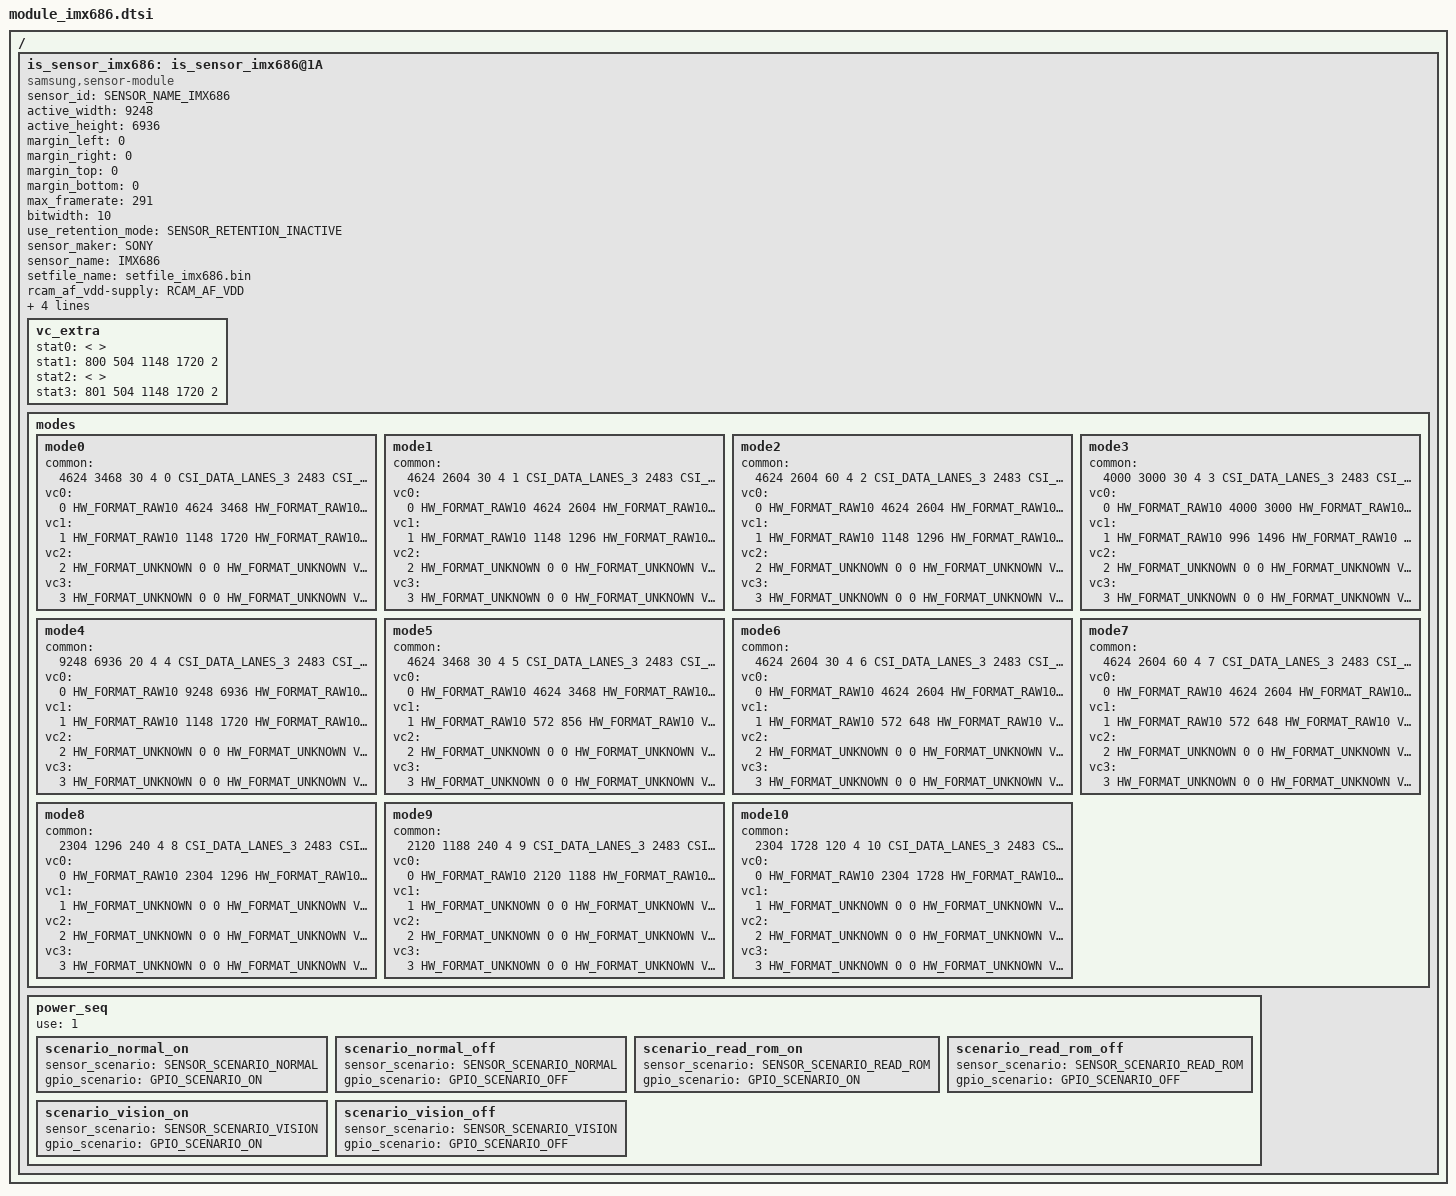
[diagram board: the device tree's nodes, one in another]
/*
 * SAMSUNG EXYNOSxxxx board camera device tree source
 *
 * Copyright (c) 2019 Samsung Electronics Co., Ltd.
 *		http://www.samsung.com
 *
 * This program is free software; you can redistribute it and/or modify
 * it under the terms of the GNU General Public License version 2 as
 * published by the Free Software Foundation.
 */

#include <dt-bindings/camera/exynos_is_dt.h>

#ifndef USE_VENDOR_PWR_PIN_NAME
#define RCAM_AF_VDD	<>
#define IMX686_AVDD1	<>
#define IMX686_AVDD2	<>
#define IMX686_DVDD	<>
#define IMX686_IOVDD	<>
#endif

/ {
	fragment@camera {
		target-path = "/";
		__overlay__ {
			is_sensor_imx686: is_sensor_imx686@1A {
				compatible = "samsung,sensor-module";

				/* common */
				sensor_id = <SENSOR_NAME_IMX686>;
				active_width = <9248>;
				active_height = <6936>;
				margin_left = <0>;
				margin_right = <0>;
				margin_top = <0>;
				margin_bottom = <0>;
				max_framerate = <291>;
				bitwidth = <10>;
				use_retention_mode = <SENSOR_RETENTION_INACTIVE>;
				sensor_maker = "SONY";
				sensor_name = "IMX686";
				setfile_name = "setfile_imx686.bin";

				rcam_af_vdd-supply = RCAM_AF_VDD;
				imx686_avdd1-supply = IMX686_AVDD1;
				imx686_avdd2-supply = IMX686_AVDD2;
				imx686_dvdd-supply = IMX686_DVDD;
				imx686_iovdd-supply = IMX686_IOVDD;

				status = "okay";

				vc_extra {
					/* ex) statX = <stat_type, sensor_mode, max_width, max_height, max_element> */
					/* VC_BUF_DATA_TYPE_SENSOR_STAT1 */
					stat0 = </* not avaliable */>;
					/* VC_BUF_DATA_TYPE_GENERAL_STAT1 */
					stat1 = </*VC_STAT_TYPE_PDP_1_1_PDAF_STAT0*/ 800    /*VC_SENSOR_MODE_IMX_2X1OCL_2_TAIL*/ 504 1148 1720 2>;
					/* VC_BUF_DATA_TYPE_SENSOR_STAT2 */
					stat2 = </* not avaliable */>;
					/* VC_BUF_DATA_TYPE_GENERAL_STAT2 */
					stat3 = </*VC_STAT_TYPE_PDP_1_1_PDAF_STAT1*/ 801    /*VC_SENSOR_MODE_IMX_2X1OCL_2_TAIL*/ 504 1148 1720 2>;
				};

/*
 * [Mode Information]
 *
 * Reference File :
 * MP version : IMX686-FAKH5-SEC-CPHY-26M_RegisterSetting_ver6.00-8.00_b8_MP_Exy_200218.xlsx
 * ES version : IMX686-FAKH5-SEC-CPHY-26M_RegisterSetting_ver6.00-7.00_b8_ES_Exy_200218.xlsx
 * Update Data    : 2020-02-20
 * Author         : takkyoum.kim
 *
 * - Global Setting with ImageQuality setting -
 *
 * - 2x2 BIN For Still Preview / Capture / Recording -
 *    [  0 ] 2Bin_A2   : 2x2 Binning 4624X3468 30fps      : Single Still Preview/Capture (4:3)   ,  MIPI lane: 3, MIPI data rate(Mbps/lane): 2483
 *    [  1 ] 2Bin_B     : 2x2 Binning 4624X2604 30fps      : Single Still Preview/Capture (16:9)  ,  MIPI lane: 3, MIPI data rate(Mbps/lane): 2483
 *    [  2 ] 2Bin_C     : 2x2 Binning 4624X2604 60fps      : Single Still Preview/Capture (16:9)  ,  MIPI lane: 3, MIPI data rate(Mbps/lane): 2483
 *    [  3 ] 2Bin_D     : 2x2 Binning 4000X3000 30fps      : Single Still Preview/Capture (4:3)   ,  MIPI lane: 3, MIPI data rate(Mbps/lane): 2483
 *
 * - Remosaic Full For Still Remosaic Capture -
 *    [  4 ] Full          : Remosaic Full 9248x6936 20fps   : Single Still Remosaic Capture (4:3)  ,  MIPI lane: 3, MIPI data rate(Mbps/lane): 2483
 *
 * - Remosaic Crop For RemosaicCropZoom Mode -
 *    [  5 ] Full_CropA2 : Remosaic Crop 4624x3468 30fps : Single Still Remosaic Preview (4:3)   ,  MIPI lane: 3, MIPI data rate(Mbps/lane): 2483
 *    [  6 ] Full_CropB  : Remosaic Crop 4624x2604 30fps : Single Still Remosaic Preview (16:9)  ,  MIPI lane: 3, MIPI data rate(Mbps/lane): 2483
 *    [  7 ] Full_CropC  : Remosaic Crop 4624x2604 60fps : Single Still Remosaic Preview (16:9)  ,  MIPI lane: 3, MIPI data rate(Mbps/lane): 2483
 *
 * - V2H2 For HighSpeed Recording/FastAE -
 *    [  8 ] V2H2_SSL    : V2H2 SlowMotion 2304x1296 240fps : Slow Motion Preview        (16:9)   ,  MIPI lane: 3, MIPI data rate(Mbps/lane): 2483
 *    [  9 ] V2H2_SSL_B : V2H2 SlowMotion 2120x1188 240fps : Slow Motion Crop Preview (16:9)   ,  MIPI lane: 3, MIPI data rate(Mbps/lane): 2483
 *    [ 10 ] V2H2_FAE    : V2H2 FastAE      2304x1728 120fps : Fast AE                          (4:3)    ,  MIPI lane: 3, MIPI data rate(Mbps/lane): 2483
 *
 * - SuperNightMode (none USED) -
 *    [ 11 ] SNM         : SuperNightMode  4624x3468 24fps   : Dual Still Preview/Capture (4:3)  ,  MIPI lane: 3, MIPI data rate(Mbps/lane): 2483
 *
 */

				/* sensor modes */
				modes {
						/* common = <width, height, fps, settle, mode, lane, speed, interleave, lrte, pd_mode> */
						/* vcX = <map, hwformat, width, height, hwformat, type, width, height> */

					/* 2x2 BIN For Single Still Preview & Capture */
					mode0 {
						common = <4624 3468 30 4 0 CSI_DATA_LANES_3 2483 CSI_MODE_VC_DT LRTE_DISABLE PD_MSPD_TAIL EX_NONE>;
						vc0 = </* in */ 0 HW_FORMAT_RAW10 4624 3468		/* out */ HW_FORMAT_RAW10 VC_NOTHING 0 0>;
						vc1 = </* in */ 1 HW_FORMAT_RAW10 1148 1720		/* out */ HW_FORMAT_RAW10 VC_NOTHING 0 0>;
						vc2 = </* in */ 2 HW_FORMAT_UNKNOWN 0 0			/* out */ HW_FORMAT_UNKNOWN VC_NOTHING 0 0>;
						vc3 = </* in */ 3 HW_FORMAT_UNKNOWN 0 0			/* out */ HW_FORMAT_UNKNOWN VC_NOTHING 0 0>;
					};
					mode1 {
						common = <4624 2604 30 4 1 CSI_DATA_LANES_3 2483 CSI_MODE_VC_DT LRTE_DISABLE PD_MSPD_TAIL EX_NONE>;
						vc0 = </* in */ 0 HW_FORMAT_RAW10 4624 2604		/* out */ HW_FORMAT_RAW10 VC_NOTHING 0 0>;
						vc1 = </* in */ 1 HW_FORMAT_RAW10 1148 1296		/* out */ HW_FORMAT_RAW10 VC_NOTHING 0 0>;
						vc2 = </* in */ 2 HW_FORMAT_UNKNOWN 0 0			/* out */ HW_FORMAT_UNKNOWN VC_NOTHING 0 0>;
						vc3 = </* in */ 3 HW_FORMAT_UNKNOWN 0 0			/* out */ HW_FORMAT_UNKNOWN VC_NOTHING 0 0>;
					};
					mode2 {
						common = <4624 2604 60 4 2 CSI_DATA_LANES_3 2483 CSI_MODE_VC_DT LRTE_DISABLE PD_MSPD_TAIL EX_NONE>;
						vc0 = </* in */ 0 HW_FORMAT_RAW10 4624 2604		/* out */ HW_FORMAT_RAW10 VC_NOTHING 0 0>;
						vc1 = </* in */ 1 HW_FORMAT_RAW10 1148 1296		/* out */ HW_FORMAT_RAW10 VC_NOTHING 0 0>;
						vc2 = </* in */ 2 HW_FORMAT_UNKNOWN 0 0			/* out */ HW_FORMAT_UNKNOWN VC_NOTHING 0 0>;
						vc3 = </* in */ 3 HW_FORMAT_UNKNOWN 0 0			/* out */ HW_FORMAT_UNKNOWN VC_NOTHING 0 0>;
					};
					mode3 {
						common = <4000 3000 30 4 3 CSI_DATA_LANES_3 2483 CSI_MODE_VC_DT LRTE_DISABLE PD_MSPD_TAIL EX_NONE>;
						vc0 = </* in */ 0 HW_FORMAT_RAW10 4000 3000		/* out */ HW_FORMAT_RAW10 VC_NOTHING 0 0>;
						vc1 = </* in */ 1 HW_FORMAT_RAW10 996 1496		/* out */ HW_FORMAT_RAW10 VC_NOTHING 0 0>;
						vc2 = </* in */ 2 HW_FORMAT_UNKNOWN 0 0			/* out */ HW_FORMAT_UNKNOWN VC_NOTHING 0 0>;
						vc3 = </* in */ 3 HW_FORMAT_UNKNOWN 0 0			/* out */ HW_FORMAT_UNKNOWN VC_NOTHING 0 0>;
					};

					/* REMOSAIC For Single Still Preview & Capture */
					mode4 {
						common = <9248 6936 20 4 4 CSI_DATA_LANES_3 2483 CSI_MODE_VC_DT LRTE_DISABLE PD_MSPD_TAIL EX_NONE>;
						vc0 = </* in */ 0 HW_FORMAT_RAW10 9248 6936		/* out */ HW_FORMAT_RAW10 VC_NOTHING 0 0>;
						vc1 = </* in */ 1 HW_FORMAT_RAW10 1148 1720		/* out */ HW_FORMAT_RAW10 VC_NOTHING 0 0>;
						vc2 = </* in */ 2 HW_FORMAT_UNKNOWN 0 0			/* out */ HW_FORMAT_UNKNOWN VC_NOTHING 0 0>;
						vc3 = </* in */ 3 HW_FORMAT_UNKNOWN 0 0			/* out */ HW_FORMAT_UNKNOWN VC_NOTHING 0 0>;
					};

					/* REMOSAIC CROP For RemosaicCropZoom Mode */
					mode5 {
						common = <4624 3468 30 4 5 CSI_DATA_LANES_3 2483 CSI_MODE_VC_DT LRTE_DISABLE PD_MSPD_TAIL EX_LOW_RES_TETRA>;
						vc0 = </* in */ 0 HW_FORMAT_RAW10 4624 3468		/* out */ HW_FORMAT_RAW10 VC_NOTHING 0 0>;
						vc1 = </* in */ 1 HW_FORMAT_RAW10 572 856		/* out */ HW_FORMAT_RAW10 VC_NOTHING 0 0>;
						vc2 = </* in */ 2 HW_FORMAT_UNKNOWN 0 0			/* out */ HW_FORMAT_UNKNOWN VC_NOTHING 0 0>;
						vc3 = </* in */ 3 HW_FORMAT_UNKNOWN 0 0			/* out */ HW_FORMAT_UNKNOWN VC_NOTHING 0 0>;
					};
					mode6 {
						common = <4624 2604 30 4 6 CSI_DATA_LANES_3 2483 CSI_MODE_VC_DT LRTE_DISABLE PD_MSPD_TAIL EX_LOW_RES_TETRA>;
						vc0 = </* in */ 0 HW_FORMAT_RAW10 4624 2604		/* out */ HW_FORMAT_RAW10 VC_NOTHING 0 0>;
						vc1 = </* in */ 1 HW_FORMAT_RAW10 572 648		/* out */ HW_FORMAT_RAW10 VC_NOTHING 0 0>;
						vc2 = </* in */ 2 HW_FORMAT_UNKNOWN 0 0			/* out */ HW_FORMAT_UNKNOWN VC_NOTHING 0 0>;
						vc3 = </* in */ 3 HW_FORMAT_UNKNOWN 0 0			/* out */ HW_FORMAT_UNKNOWN VC_NOTHING 0 0>;
					};
					mode7 {
						common = <4624 2604 60 4 7 CSI_DATA_LANES_3 2483 CSI_MODE_VC_DT LRTE_DISABLE PD_MSPD_TAIL EX_LOW_RES_TETRA>;
						vc0 = </* in */ 0 HW_FORMAT_RAW10 4624 2604		/* out */ HW_FORMAT_RAW10 VC_NOTHING 0 0>;
						vc1 = </* in */ 1 HW_FORMAT_RAW10 572 648		/* out */ HW_FORMAT_RAW10 VC_NOTHING 0 0>;
						vc2 = </* in */ 2 HW_FORMAT_UNKNOWN 0 0			/* out */ HW_FORMAT_UNKNOWN VC_NOTHING 0 0>;
						vc3 = </* in */ 3 HW_FORMAT_UNKNOWN 0 0			/* out */ HW_FORMAT_UNKNOWN VC_NOTHING 0 0>;
					};

					/* V2H2 For HighSpeed Recording & FastAE */
					mode8{
						common = <2304 1296 240 4 8 CSI_DATA_LANES_3 2483 CSI_MODE_VC_DT LRTE_DISABLE PD_NONE EX_NONE>;
						vc0 = </* in */ 0 HW_FORMAT_RAW10 2304 1296		/* out */ HW_FORMAT_RAW10 VC_NOTHING 0 0>;
						vc1 = </* in */ 1 HW_FORMAT_UNKNOWN 0 0			/* out */ HW_FORMAT_UNKNOWN VC_NOTHING 0 0>;
						vc2 = </* in */ 2 HW_FORMAT_UNKNOWN 0 0			/* out */ HW_FORMAT_UNKNOWN VC_NOTHING 0 0>;
						vc3 = </* in */ 3 HW_FORMAT_UNKNOWN 0 0			/* out */ HW_FORMAT_UNKNOWN VC_NOTHING 0 0>;
					};
					mode9{
						common = <2120 1188 240 4 9 CSI_DATA_LANES_3 2483 CSI_MODE_VC_DT LRTE_DISABLE PD_NONE EX_NONE>;
						vc0 = </* in */ 0 HW_FORMAT_RAW10 2120 1188		/* out */ HW_FORMAT_RAW10 VC_NOTHING 0 0>;
						vc1 = </* in */ 1 HW_FORMAT_UNKNOWN 0 0			/* out */ HW_FORMAT_UNKNOWN VC_NOTHING 0 0>;
						vc2 = </* in */ 2 HW_FORMAT_UNKNOWN 0 0			/* out */ HW_FORMAT_UNKNOWN VC_NOTHING 0 0>;
						vc3 = </* in */ 3 HW_FORMAT_UNKNOWN 0 0			/* out */ HW_FORMAT_UNKNOWN VC_NOTHING 0 0>;
					};
					mode10{
						common = <2304 1728 120 4 10 CSI_DATA_LANES_3 2483 CSI_MODE_VC_DT LRTE_DISABLE PD_NONE EX_NONE>;
						vc0 = </* in */ 0 HW_FORMAT_RAW10 2304 1728		/* out */ HW_FORMAT_RAW10 VC_NOTHING 0 0>;
						vc1 = </* in */ 1 HW_FORMAT_UNKNOWN 0 0			/* out */ HW_FORMAT_UNKNOWN VC_NOTHING 0 0>;
						vc2 = </* in */ 2 HW_FORMAT_UNKNOWN 0 0			/* out */ HW_FORMAT_UNKNOWN VC_NOTHING 0 0>;
						vc3 = </* in */ 3 HW_FORMAT_UNKNOWN 0 0			/* out */ HW_FORMAT_UNKNOWN VC_NOTHING 0 0>;
					};
#if 0
					/* SuperNightMode (none USED) */
					mode11{
						common = <4624 3468 24 4 11 CSI_DATA_LANES_3 2483 CSI_MODE_VC_DT LRTE_DISABLE PD_MSPD_TAIL EX_NONE>;
						vc0 = </* in */ 0 HW_FORMAT_RAW10 4624 3468		/* out */ HW_FORMAT_RAW10 VC_NOTHING 0 0>;
						vc1 = </* in */ 1 HW_FORMAT_RAW10 1148 1720		/* out */ HW_FORMAT_RAW10 VC_NOTHING 0 0>;
						vc2 = </* in */ 2 HW_FORMAT_UNKNOWN 0 0			/* out */ HW_FORMAT_UNKNOWN VC_NOTHING 0 0>;
						vc3 = </* in */ 3 HW_FORMAT_UNKNOWN 0 0			/* out */ HW_FORMAT_UNKNOWN VC_NOTHING 0 0>;
					};
#endif
				};

				power_seq {
					use = <1>;
					scenario_normal_on {
						sensor_scenario = <SENSOR_SCENARIO_NORMAL>;
						gpio_scenario = <GPIO_SCENARIO_ON>;

						/* A start node number should be over the 10 for reserved number 0~9. */
						/* pname = "name"; 		pin = <act value dealy voltage>;	gpio = <gpx# # 0x1>; */
					};

					scenario_normal_off {
						sensor_scenario = <SENSOR_SCENARIO_NORMAL>;
						gpio_scenario = <GPIO_SCENARIO_OFF>;

						/* A start node number should be over the 10 for reserved number 0~9. */
						/* pname = "name"; 		pin = <act value dealy voltage>;	gpio = <gpx# # 0x1>; */
					};

					scenario_read_rom_on {
						sensor_scenario = <SENSOR_SCENARIO_READ_ROM>;
						gpio_scenario = <GPIO_SCENARIO_ON>;

						/* A start node number should be over the 10 for reserved number 0~9. */
						/* pname = "name";		pin = <act value dealy voltage>;	gpio = <gpx# # 0x1>; */
					};

					scenario_read_rom_off {
						sensor_scenario = <SENSOR_SCENARIO_READ_ROM>;
						gpio_scenario = <GPIO_SCENARIO_OFF>;

						/* A start node number should be over the 10 for reserved number 0~9. */
						/* pname = "name"; 		pin = <act value dealy voltage>; 	gpio = <gpx# # 0x1>; */
					};

					scenario_vision_on {
						sensor_scenario = <SENSOR_SCENARIO_VISION>;
						gpio_scenario = <GPIO_SCENARIO_ON>;

						/* A start node number should be over the 10 for reserved number 0~9. */
						/* pname = "name"; 		pin = <act value dealy voltage>;	gpio = <gpx# # 0x1>; */
					};

					scenario_vision_off {
						sensor_scenario = <SENSOR_SCENARIO_VISION>;
						gpio_scenario = <GPIO_SCENARIO_OFF>;

						/* A start node number should be over the 10 for reserved number 0~9. */
						/* pname = "name"; 		pin = <act value dealy voltage>;	gpio = <gpx# # 0x1>; */
					};
				};
			};
		}; /* end of __overlay__ */
	}; /* end of fragment */
}; /* end of root */

